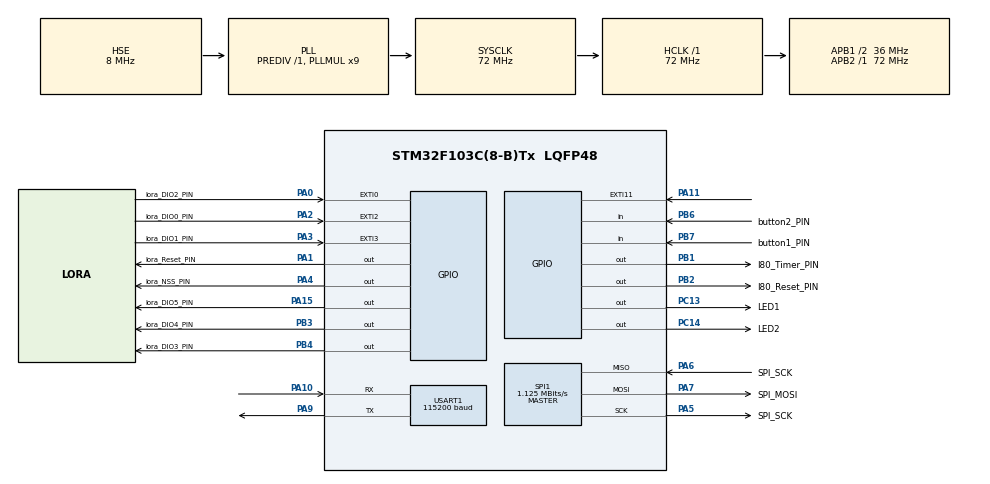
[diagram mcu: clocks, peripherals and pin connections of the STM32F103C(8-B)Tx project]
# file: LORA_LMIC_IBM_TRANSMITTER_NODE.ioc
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Mcu.Family=STM32F1
Mcu.Name=STM32F103C(8-B)Tx
Mcu.Package=LQFP48
NVIC.EXTI0_IRQn=true\:0\:0\:false\:false\:true\:true
NVIC.EXTI2_IRQn=true\:0\:0\:false\:false\:true\:true
NVIC.EXTI3_IRQn=true\:0\:0\:false\:false\:true\:true
NVIC.PriorityGroup=NVIC_PRIORITYGROUP_4
NVIC.SPI1_IRQn=true\:0\:0\:false\:false\:true\:true
NVIC.TIM4_IRQn=true\:0\:0\:false\:false\:true\:true
NVIC.USART1_IRQn=true\:0\:0\:false\:false\:true\:true
PA0-WKUP.GPIO_Label=lora_DIO2_PIN
PA0-WKUP.Signal=GPXTI0
PA1.GPIO_Label=lora_Reset_PIN
PA1.Signal=GPIO_Output
PA10.GPIO_PuPd=GPIO_PULLUP
PA10.Mode=Asynchronous
PA10.Signal=USART1_RX
PA11.Signal=GPXTI11
PA13.Mode=Serial_Wire
PA13.Signal=SYS_JTMS-SWDIO
PA14.Mode=Serial_Wire
PA14.Signal=SYS_JTCK-SWCLK
PA15.GPIO_Label=lora_DIO5_PIN
PA15.Signal=GPIO_Output
PA2.GPIO_Label=lora_DIO0_PIN
PA2.Signal=GPXTI2
PA3.GPIO_Label=lora_DIO1_PIN
PA3.Signal=GPXTI3
PA4.GPIO_Label=lora_NSS_PIN
PA4.Signal=GPIO_Output
PA5.GPIO_Label=SPI_SCK
PA5.Mode=Full_Duplex_Master
PA5.Signal=SPI1_SCK
PA6.GPIO_Label=SPI_SCK
PA6.Mode=Full_Duplex_Master
PA6.Signal=SPI1_MISO
PA7.GPIO_Label=SPI_MOSI
PA7.Mode=Full_Duplex_Master
PA7.Signal=SPI1_MOSI
PA9.Mode=Asynchronous
PA9.Signal=USART1_TX
PB1.GPIO_Label=l80_Timer_PIN
PB1.Signal=GPIO_Output
PB2.GPIO_Label=l80_Reset_PIN
PB2.Signal=GPIO_Output
PB3.GPIO_Label=lora_DIO4_PIN
PB3.Signal=GPIO_Output
PB4.GPIO_Label=lora_DIO3_PIN
PB4.Signal=GPIO_Output
PB6.GPIO_Label=button2_PIN
PB6.Signal=GPIO_Input
PB7.GPIO_Label=button1_PIN
PB7.Signal=GPIO_Input
PC13-TAMPER-RTC.GPIO_Label=LED1
PC13-TAMPER-RTC.Signal=GPIO_Output
PC14-OSC32_IN.GPIO_Label=LED2
PC14-OSC32_IN.Signal=GPIO_Output
PD0-OSC_IN.Mode=HSE-External-Oscillator
PD0-OSC_IN.Signal=RCC_OSC_IN
PD1-OSC_OUT.Mode=HSE-External-Oscillator
PD1-OSC_OUT.Signal=RCC_OSC_OUT
ProjectManager.HeapSize=0x200
ProjectManager.StackSize=0x400
ProjectManager.TargetToolchain=SW4STM32
RCC.AHBFreq_Value=72000000
RCC.APB1CLKDivider=RCC_HCLK_DIV2
RCC.APB1Freq_Value=36000000
RCC.APB1TimFreq_Value=72000000
RCC.APB2Freq_Value=72000000
RCC.APB2TimFreq_Value=72000000
RCC.HCLKFreq_Value=72000000
RCC.PLLMUL=RCC_PLL_MUL9
RCC.PLLSourceVirtual=RCC_PLLSOURCE_HSE
RCC.SYSCLKFreq_VALUE=72000000
RCC.SYSCLKSource=RCC_SYSCLKSOURCE_PLLCLK
RCC.USBFreq_Value=48000000
RCC.USBPrescaler=RCC_USBCLKSOURCE_PLL_DIV1_5
SPI1.BaudRatePrescaler=SPI_BAUDRATEPRESCALER_64
SPI1.CalculateBaudRate=1.125 MBits/s
SPI1.Direction=SPI_DIRECTION_2LINES
SPI1.Mode=SPI_MODE_MASTER
SPI1.VirtualNSS=VM_NSSHARD
SPI1.VirtualType=VM_MASTER
TIM4.Channel-Output\ Compare1\ No\ Output=TIM_CHANNEL_1
TIM4.Period=65535-1
TIM4.Prescaler=2250-1
USART1.BaudRate=115200
USART1.VirtualMode=VM_ASYNC
VP_TIM4_VS_no_output1.Mode=Output Compare1 No Output
board=custom

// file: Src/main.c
/* USER CODE BEGIN Header */
/**
  ******************************************************************************
  * @file           : main.c
  * @brief          : Main program body
  * @author			: Dhananjay Khairnar
  * @email			: khairnardm@gmail.com
  ******************************************************************************
  ** This notice applies to any and all portions of this file
  * that are not between comment pairs USER CODE BEGIN and
  * USER CODE END. Other portions of this file, whether
  * inserted by the user or by software development tools
  * are owned by their respective copyright owners.
  *
  * COPYRIGHT(c) 2019 STMicroelectronics
  *
  * Redistribution and use in source and binary forms, with or without modification,
  * are permitted provided that the following conditions are met:
  *   1. Redistributions of source code must retain the above copyright notice,
  *      this list of conditions and the following disclaimer.
  *   2. Redistributions in binary form must reproduce the above copyright notice,
  *      this list of conditions and the following disclaimer in the documentation
  *      and/or other materials provided with the distribution.
  *   3. Neither the name of STMicroelectronics nor the names of its contributors
  *      may be used to endorse or promote products derived from this software
  *      without specific prior written permission.
  *
  * THIS SOFTWARE IS PROVIDED BY THE COPYRIGHT HOLDERS AND CONTRIBUTORS "AS IS"
  * AND ANY EXPRESS OR IMPLIED WARRANTIES, INCLUDING, BUT NOT LIMITED TO, THE
  * IMPLIED WARRANTIES OF MERCHANTABILITY AND FITNESS FOR A PARTICULAR PURPOSE ARE
  * DISCLAIMED. IN NO EVENT SHALL THE COPYRIGHT HOLDER OR CONTRIBUTORS BE LIABLE
  * FOR ANY DIRECT, INDIRECT, INCIDENTAL, SPECIAL, EXEMPLARY, OR CONSEQUENTIAL
  * DAMAGES (INCLUDING, BUT NOT LIMITED TO, PROCUREMENT OF SUBSTITUTE GOODS OR
  * SERVICES; LOSS OF USE, DATA, OR PROFITS; OR BUSINESS INTERRUPTION) HOWEVER
  * CAUSED AND ON ANY THEORY OF LIABILITY, WHETHER IN CONTRACT, STRICT LIABILITY,
  * OR TORT (INCLUDING NEGLIGENCE OR OTHERWISE) ARISING IN ANY WAY OUT OF THE USE
  * OF THIS SOFTWARE, EVEN IF ADVISED OF THE POSSIBILITY OF SUCH DAMAGE.
  *
  ******************************************************************************
  */
/* USER CODE END Header */

#include "main.h"

/* USER CODE BEGIN Includes */
#include "mainApp.h"
/* USER CODE END Includes */

SPI_HandleTypeDef hspi1;

TIM_HandleTypeDef htim4;

UART_HandleTypeDef huart1;

/* USER CODE BEGIN PV */
/* Private variables ---------------------------------------------------------*/

/* USER CODE END PV */

void SystemClock_Config(void);
static void MX_GPIO_Init(void);
static void MX_USART1_UART_Init(void);
static void MX_SPI1_Init(void);
static void MX_TIM4_Init(void);
/* USER CODE BEGIN PFP */
/* Private function prototypes -----------------------------------------------*/

/* USER CODE END PFP */

int main(void)
{

  /* MCU Configuration--------------------------------------------------------*/

  /* Reset of all peripherals, Initializes the Flash interface and the Systick. */
  HAL_Init();

  /* Configure the system clock */
  SystemClock_Config();

  /* Initialize all configured peripherals */
  MX_GPIO_Init();
  MX_USART1_UART_Init();
  MX_SPI1_Init();
  MX_TIM4_Init();
  /* USER CODE BEGIN 2 */
  HAL_TIM_Base_Start_IT(&htim4);    // <-----------  change to your setup
   __HAL_SPI_ENABLE(&hspi1);         // <-----------  change to your setup
  /* USER CODE END 2 */

  /* Infinite loop */
  while (1)
  {

    /* USER CODE BEGIN 3 */
	  HAL_UART_Transmit(&huart1,"Program Start\n",sizeof("Program Start\n"),5);
	  mainApp();
  }
  /* USER CODE END 3 */
}

void SystemClock_Config(void)
{
  RCC_OscInitTypeDef RCC_OscInitStruct = {0};
  RCC_ClkInitTypeDef RCC_ClkInitStruct = {0};

  /**Initializes the CPU, AHB and APB busses clocks
  */
  RCC_OscInitStruct.OscillatorType = RCC_OSCILLATORTYPE_HSE;
  RCC_OscInitStruct.HSEState = RCC_HSE_ON;
  RCC_OscInitStruct.HSEPredivValue = RCC_HSE_PREDIV_DIV1;
  RCC_OscInitStruct.HSIState = RCC_HSI_ON;
  RCC_OscInitStruct.PLL.PLLState = RCC_PLL_ON;
  RCC_OscInitStruct.PLL.PLLSource = RCC_PLLSOURCE_HSE;
  RCC_OscInitStruct.PLL.PLLMUL = RCC_PLL_MUL9;
  if (HAL_RCC_OscConfig(&RCC_OscInitStruct) != HAL_OK)
  {
    Error_Handler();
  }
  /**Initializes the CPU, AHB and APB busses clocks
  */
  RCC_ClkInitStruct.ClockType = RCC_CLOCKTYPE_HCLK|RCC_CLOCKTYPE_SYSCLK
                              |RCC_CLOCKTYPE_PCLK1|RCC_CLOCKTYPE_PCLK2;
  RCC_ClkInitStruct.SYSCLKSource = RCC_SYSCLKSOURCE_PLLCLK;
  RCC_ClkInitStruct.AHBCLKDivider = RCC_SYSCLK_DIV1;
  RCC_ClkInitStruct.APB1CLKDivider = RCC_HCLK_DIV2;
  RCC_ClkInitStruct.APB2CLKDivider = RCC_HCLK_DIV1;

  if (HAL_RCC_ClockConfig(&RCC_ClkInitStruct, FLASH_LATENCY_2) != HAL_OK)
  {
    Error_Handler();
  }
}

static void MX_SPI1_Init(void)
{

  /* SPI1 parameter configuration*/
  hspi1.Instance = SPI1;
  hspi1.Init.Mode = SPI_MODE_MASTER;
  hspi1.Init.Direction = SPI_DIRECTION_2LINES;
  hspi1.Init.DataSize = SPI_DATASIZE_8BIT;
  hspi1.Init.CLKPolarity = SPI_POLARITY_LOW;
  hspi1.Init.CLKPhase = SPI_PHASE_1EDGE;
  hspi1.Init.NSS = SPI_NSS_SOFT;
  hspi1.Init.BaudRatePrescaler = SPI_BAUDRATEPRESCALER_64;
  hspi1.Init.FirstBit = SPI_FIRSTBIT_MSB;
  hspi1.Init.TIMode = SPI_TIMODE_DISABLE;
  hspi1.Init.CRCCalculation = SPI_CRCCALCULATION_DISABLE;
  hspi1.Init.CRCPolynomial = 10;
  if (HAL_SPI_Init(&hspi1) != HAL_OK)
  {
    Error_Handler();
  }

}

static void MX_TIM4_Init(void)
{

  TIM_MasterConfigTypeDef sMasterConfig = {0};
  TIM_OC_InitTypeDef sConfigOC = {0};

  htim4.Instance = TIM4;
  htim4.Init.Prescaler = 2250-1;
  htim4.Init.CounterMode = TIM_COUNTERMODE_UP;
  htim4.Init.Period = 65535-1;
  htim4.Init.ClockDivision = TIM_CLOCKDIVISION_DIV1;
  htim4.Init.AutoReloadPreload = TIM_AUTORELOAD_PRELOAD_DISABLE;
  if (HAL_TIM_OC_Init(&htim4) != HAL_OK)
  {
    Error_Handler();
  }
  sMasterConfig.MasterOutputTrigger = TIM_TRGO_RESET;
  sMasterConfig.MasterSlaveMode = TIM_MASTERSLAVEMODE_DISABLE;
  if (HAL_TIMEx_MasterConfigSynchronization(&htim4, &sMasterConfig) != HAL_OK)
  {
    Error_Handler();
  }
  sConfigOC.OCMode = TIM_OCMODE_TIMING;
  sConfigOC.Pulse = 0;
  sConfigOC.OCPolarity = TIM_OCPOLARITY_HIGH;
  sConfigOC.OCFastMode = TIM_OCFAST_DISABLE;
  if (HAL_TIM_OC_ConfigChannel(&htim4, &sConfigOC, TIM_CHANNEL_1) != HAL_OK)
  {
    Error_Handler();
  }

}

static void MX_USART1_UART_Init(void)
{

  huart1.Instance = USART1;
  huart1.Init.BaudRate = 115200;
  huart1.Init.WordLength = UART_WORDLENGTH_8B;
  huart1.Init.StopBits = UART_STOPBITS_1;
  huart1.Init.Parity = UART_PARITY_NONE;
  huart1.Init.Mode = UART_MODE_TX_RX;
  huart1.Init.HwFlowCtl = UART_HWCONTROL_NONE;
  huart1.Init.OverSampling = UART_OVERSAMPLING_16;
  if (HAL_UART_Init(&huart1) != HAL_OK)
  {
    Error_Handler();
  }

}

static void MX_GPIO_Init(void)
{
  GPIO_InitTypeDef GPIO_InitStruct = {0};

  /* GPIO Ports Clock Enable */
  __HAL_RCC_GPIOC_CLK_ENABLE();
  __HAL_RCC_GPIOD_CLK_ENABLE();
  __HAL_RCC_GPIOA_CLK_ENABLE();
  __HAL_RCC_GPIOB_CLK_ENABLE();

  /*Configure GPIO pin Output Level */
  HAL_GPIO_WritePin(GPIOC, LED1_Pin|LED2_Pin, GPIO_PIN_RESET);

  /*Configure GPIO pin Output Level */
  HAL_GPIO_WritePin(GPIOA, lora_Reset_PIN_Pin|lora_NSS_PIN_Pin|lora_DIO5_PIN_Pin, GPIO_PIN_RESET);

  /*Configure GPIO pin Output Level */
  HAL_GPIO_WritePin(GPIOB, l80_Timer_PIN_Pin|l80_Reset_PIN_Pin|lora_DIO4_PIN_Pin|lora_DIO3_PIN_Pin, GPIO_PIN_RESET);

  /*Configure GPIO pins : LED1_Pin LED2_Pin */
  GPIO_InitStruct.Pin = LED1_Pin|LED2_Pin;
  GPIO_InitStruct.Mode = GPIO_MODE_OUTPUT_PP;
  GPIO_InitStruct.Pull = GPIO_NOPULL;
  GPIO_InitStruct.Speed = GPIO_SPEED_FREQ_LOW;
  HAL_GPIO_Init(GPIOC, &GPIO_InitStruct);

  /*Configure GPIO pins : lora_DIO2_PIN_Pin lora_DIO0_PIN_Pin lora_DIO1_PIN_Pin PA11 */
  GPIO_InitStruct.Pin = lora_DIO2_PIN_Pin|lora_DIO0_PIN_Pin|lora_DIO1_PIN_Pin|GPIO_PIN_11;
  GPIO_InitStruct.Mode = GPIO_MODE_IT_RISING;
  GPIO_InitStruct.Pull = GPIO_NOPULL;
  HAL_GPIO_Init(GPIOA, &GPIO_InitStruct);

  /*Configure GPIO pins : lora_Reset_PIN_Pin lora_NSS_PIN_Pin lora_DIO5_PIN_Pin */
  GPIO_InitStruct.Pin = lora_Reset_PIN_Pin|lora_NSS_PIN_Pin|lora_DIO5_PIN_Pin;
  GPIO_InitStruct.Mode = GPIO_MODE_OUTPUT_PP;
  GPIO_InitStruct.Pull = GPIO_NOPULL;
  GPIO_InitStruct.Speed = GPIO_SPEED_FREQ_LOW;
  HAL_GPIO_Init(GPIOA, &GPIO_InitStruct);

  /*Configure GPIO pins : l80_Timer_PIN_Pin l80_Reset_PIN_Pin lora_DIO4_PIN_Pin lora_DIO3_PIN_Pin */
  GPIO_InitStruct.Pin = l80_Timer_PIN_Pin|l80_Reset_PIN_Pin|lora_DIO4_PIN_Pin|lora_DIO3_PIN_Pin;
  GPIO_InitStruct.Mode = GPIO_MODE_OUTPUT_PP;
  GPIO_InitStruct.Pull = GPIO_NOPULL;
  GPIO_InitStruct.Speed = GPIO_SPEED_FREQ_LOW;
  HAL_GPIO_Init(GPIOB, &GPIO_InitStruct);

  /*Configure GPIO pins : button2_PIN_Pin button1_PIN_Pin */
  GPIO_InitStruct.Pin = button2_PIN_Pin|button1_PIN_Pin;
  GPIO_InitStruct.Mode = GPIO_MODE_INPUT;
  GPIO_InitStruct.Pull = GPIO_NOPULL;
  HAL_GPIO_Init(GPIOB, &GPIO_InitStruct);

  /* EXTI interrupt init*/
  HAL_NVIC_SetPriority(EXTI0_IRQn, 0, 0);
  HAL_NVIC_EnableIRQ(EXTI0_IRQn);

  HAL_NVIC_SetPriority(EXTI2_IRQn, 0, 0);
  HAL_NVIC_EnableIRQ(EXTI2_IRQn);

  HAL_NVIC_SetPriority(EXTI3_IRQn, 0, 0);
  HAL_NVIC_EnableIRQ(EXTI3_IRQn);

}

void Error_Handler(void)
{
  while(1)
  {
  }
}

/************************ (C) COPYRIGHT STMicroelectronics *****END OF FILE****/
